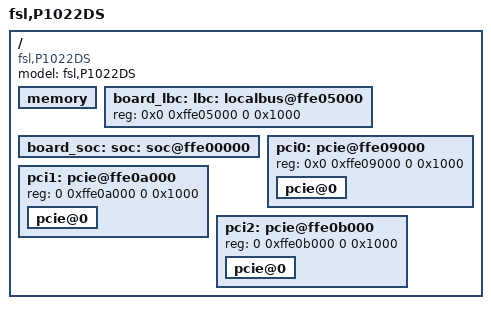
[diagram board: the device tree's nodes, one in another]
/include/ "p1022si-pre.dtsi"
/ {
	model = "fsl,P1022DS";
	compatible = "fsl,P1022DS";
	memory {
		device_type = "memory";
	};
	board_lbc: lbc: localbus@ffe05000 {
		ranges = <0x0 0x0 0x0 0xe8000000 0x08000000
			  0x1 0x0 0x0 0xe0000000 0x08000000
			  0x2 0x0 0x0 0xff800000 0x00040000
			  0x3 0x0 0x0 0xffdf0000 0x00008000>;
		reg = <0x0 0xffe05000 0 0x1000>;
	};
	board_soc: soc: soc@ffe00000 {
		ranges = <0x0 0x0 0xffe00000 0x100000>;
	};
	pci0: pcie@ffe09000 {
		ranges = <0x2000000 0x0 0xe0000000 0 0xa0000000 0x0 0x20000000
			  0x1000000 0x0 0x00000000 0 0xffc10000 0x0 0x10000>;
		reg = <0x0 0xffe09000 0 0x1000>;
		pcie@0 {
			ranges = <0x2000000 0x0 0xe0000000
				  0x2000000 0x0 0xe0000000
				  0x0 0x20000000
				  0x1000000 0x0 0x0
				  0x1000000 0x0 0x0
				  0x0 0x100000>;
		};
	};
	pci1: pcie@ffe0a000 {
		ranges = <0x2000000 0x0 0xe0000000 0 0xc0000000 0x0 0x20000000
			  0x1000000 0x0 0x00000000 0 0xffc20000 0x0 0x10000>;
		reg = <0 0xffe0a000 0 0x1000>;
		pcie@0 {
			ranges = <0x2000000 0x0 0xe0000000
				  0x2000000 0x0 0xe0000000
				  0x0 0x20000000
				  0x1000000 0x0 0x0
				  0x1000000 0x0 0x0
				  0x0 0x100000>;
		};
	};
	pci2: pcie@ffe0b000 {
		ranges = <0x2000000 0x0 0xe0000000 0 0x80000000 0x0 0x20000000
			  0x1000000 0x0 0x00000000 0 0xffc00000 0x0 0x10000>;
		reg = <0 0xffe0b000 0 0x1000>;
		pcie@0 {
			ranges = <0x2000000 0x0 0xe0000000
				  0x2000000 0x0 0xe0000000
				  0x0 0x20000000
				  0x1000000 0x0 0x0
				  0x1000000 0x0 0x0
				  0x0 0x100000>;
		};
	};
};
/include/ "p1022si-post.dtsi"
/include/ "p1022ds.dtsi"
